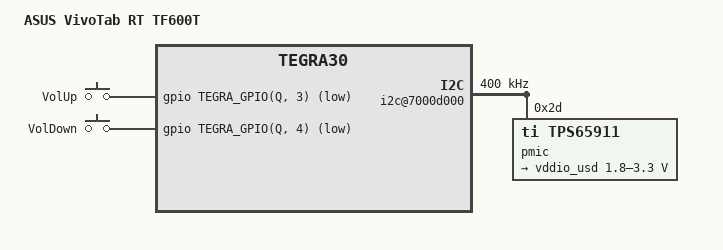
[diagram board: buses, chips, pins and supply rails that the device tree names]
// SPDX-License-Identifier: GPL-2.0-or-later
/dts-v1/;

#include "tegra30-asus-transformer.dtsi"

/ {
	model = "ASUS VivoTab RT TF600T";

	i2c@7000d000 {
		status = "okay";
		clock-frequency = <400000>;

		/* Texas Instruments TPS659110 PMIC */
		pmic: tps65911@2d {
			compatible = "ti,tps65911";
			reg = <0x2d>;

			interrupts = <GIC_SPI 86 IRQ_TYPE_LEVEL_HIGH>;
			#interrupt-cells = <2>;
			interrupt-controller;

			ti,system-power-controller;

			#gpio-cells = <2>;
			gpio-controller;

			regulators {
				/* uSD slot VDDIO */
				vddio_usd: ldo5 {
					regulator-name = "vddio_sdmmc";
					regulator-min-microvolt = <1800000>;
					regulator-max-microvolt = <3300000>;
					regulator-always-on;
				};
			};
		};
	};

	sdmmc1: sdhci@78000000 {
		vqmmc-supply = <&vddio_usd>;
	};

	gpio-keys {
		compatible = "gpio-keys";
		interrupt-parent = <&gpio>;

		volume-up {
			label = "VolUp";
			gpios = <&gpio TEGRA_GPIO(Q, 3) GPIO_ACTIVE_LOW>;
			linux,code = <KEY_VOLUMEUP>;
		};

		volume-down {
			label = "VolDown";
			gpios = <&gpio TEGRA_GPIO(Q, 4) GPIO_ACTIVE_LOW>;
			linux,code = <KEY_VOLUMEDOWN>;
		};
	};
};
